AUTOSAR XML (schema 4.0)
package /Powertrain_Components
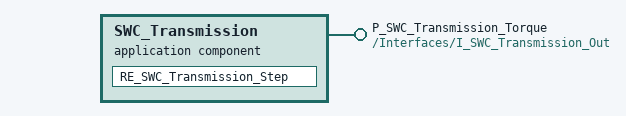
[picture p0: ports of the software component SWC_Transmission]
  application sw component type SWC_Transmission  # AUTOSAR Application SWC SWC_Transmission for Powertrain Control
    provide port P_SWC_Transmission_Torque: provided-interface=/Interfaces/I_SWC_Transmission_Out
    behavior SWC_Transmission_Behavior
      runnable RE_SWC_Transmission_Step: symbol=SWC_Transmission_Step
  sender receiver interface I_SWC_Transmission_Out
    data DE_SWC_Transmission_TorqueDemand: type=/AUTOSAR/Platform/uint32
